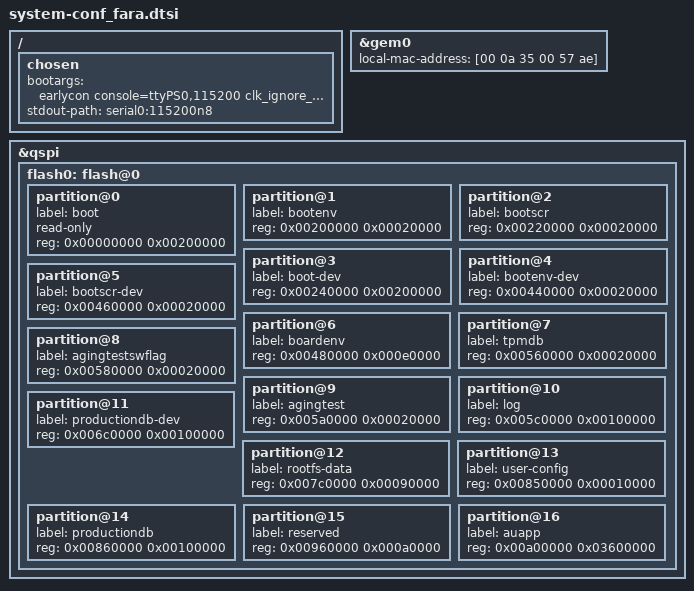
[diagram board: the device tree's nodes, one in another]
/*
 * CAUTION: This file is automatically generated by PetaLinux SDK.
 * DO NOT modify this file
 */


/ {
	chosen {
		bootargs = " earlycon console=ttyPS0,115200 clk_ignore_unused uio_pdrv_genirq.of_id=generic-uio root=/dev/ram0 rw";
		stdout-path = "serial0:115200n8";
	};
};

&gem0 {
	local-mac-address = [00 0a 35 00 57 ae];
};

&qspi {
	#address-cells = <1>;
	#size-cells = <0>;
	flash0: flash@0 {
		/delete-node/ partition@0;
		/delete-node/ partition@100000;
		/delete-node/ partition@600000;
		/delete-node/ partition@620000;
		/delete-node/ partition@c00000;
		partition@0 {
			label = "boot";
            read-only;
			reg = <0x00000000 0x00200000>;
		};
		partition@1 {
			label = "bootenv";
			reg = <0x00200000 0x00020000>;
		};
		partition@2 {
			label = "bootscr";
			reg = <0x00220000 0x00020000>;
		};
		partition@3 {
			label = "boot-dev";
			reg = <0x00240000 0x00200000>;
		};
		partition@4 {
			label = "bootenv-dev";
			reg = <0x00440000 0x00020000>;
		};
		partition@5 {
			label = "bootscr-dev";
			reg = <0x00460000 0x00020000>;
		};
		partition@6 {
			label = "boardenv";
			reg = <0x00480000 0x000e0000>;
		};
		partition@7 {
			label = "tpmdb";
			reg = <0x00560000 0x00020000>;
		};
		partition@8 {
			label = "agingtestswflag";
			reg = <0x00580000 0x00020000>;
		};
		partition@9 {
			label = "agingtest";
			reg = <0x005a0000 0x00020000>;
		};
		partition@10 {
			label = "log";
			reg = <0x005c0000 0x00100000>;
		};
		partition@11 {
			label = "productiondb-dev";
			reg = <0x006c0000 0x00100000>;
		};
		partition@12 {
			label = "rootfs-data";
			reg = <0x007c0000 0x00090000>;
		};
		partition@13 {
			label = "user-config";
			reg = <0x00850000 0x00010000>;
		};
		partition@14 {
			label = "productiondb";
			reg = <0x00860000 0x00100000>;
		};
		partition@15 {
			label = "reserved";
			reg = <0x00960000 0x000a0000>;
		};
		partition@16 {
			label = "auapp";
			reg = <0x00a00000 0x03600000>;
		};
	};
};

